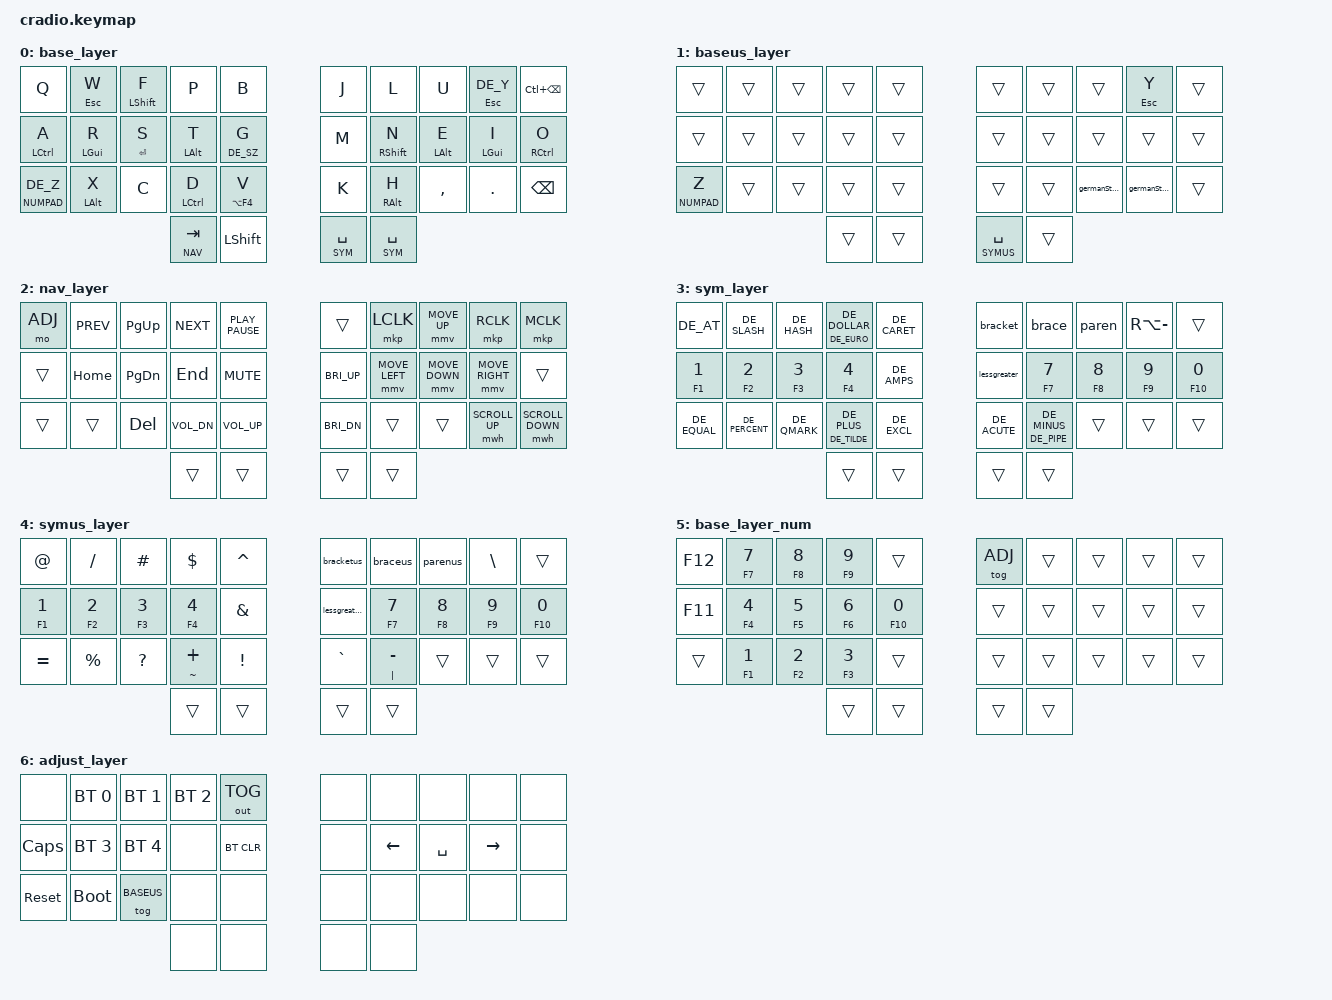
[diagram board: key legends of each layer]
/*
 * Copyright (c) 2020 The ZMK Contributors
 *
 * SPDX-License-Identifier: MIT
 */

#include <behaviors.dtsi>
#include <dt-bindings/zmk/keys.h>
#include <dt-bindings/zmk/bt.h>
#include <dt-bindings/zmk/outputs.h>
#include <dt-bindings/zmk/mouse.h>
#include <dt-bindings/zmk/ext_power.h>
#include "keys_de.h"
#include "../zmk-nodefree-config/helper.h"
#define TAPPING_TIME 25
&mmv {    
        time-to-max-speed-ms = <1000>;
        acceleration-exponent=<1>;
};
&mwh {    
        time-to-max-speed-ms = <1000>;
        acceleration-exponent=<1>;
}; 

#define U_MOUSE_MOVE_MAX 2250       // 600
#define U_MOUSE_SCROLL_MAX 100      // 10

#undef MOVE_UP
#undef MOVE_DOWN
#undef MOVE_LEFT
#undef MOVE_RIGHT
#define MOVE_UP MOVE_VERT(-U_MOUSE_MOVE_MAX)
#define MOVE_DOWN MOVE_VERT(U_MOUSE_MOVE_MAX)
#define MOVE_LEFT MOVE_HOR(-U_MOUSE_MOVE_MAX)
#define MOVE_RIGHT MOVE_HOR(U_MOUSE_MOVE_MAX)

#undef SCROLL_UP
#undef SCROLL_DOWN
#undef SCROLL_LEFT
#undef SCROLL_RIGHT
#define SCROLL_UP SCROLL_VERT(U_MOUSE_SCROLL_MAX)
#define SCROLL_DOWN SCROLL_VERT(-U_MOUSE_SCROLL_MAX)
#define SCROLL_LEFT SCROLL_HOR(-U_MOUSE_SCROLL_MAX)
#define SCROLL_RIGHT SCROLL_HOR(U_MOUSE_SCROLL_MAX)





#define XXX &none
#define ___ &trans

#define BASE 0
#define BASEUS 1
#define NAV 2
#define SYM 3
#define SYMUS 4
#define NUMPAD 5
#define ADJ 6


        /*                KEY POSITIONS
  ╭────────────────────╮ ╭────────────────────╮
  │  0   1   2   3   4 │ │  5   6   7   8   9 │
  │ 10  11  12  13  14 │ │ 15  16  17  18  19 │
  │ 20  21  22  23  24 │ │ 25  26  27  28  29 │
  ╰───────────╮ 30  31 │ │ 32  33 ╭───────────╯
              ╰────────╯ ╰────────╯            */


ZMK_COMBO(pwr,  &kp C_POWER, 0 4, ALL)
ZMK_COMBO(f23,  &kp F23, 10 20, ALL)
ZMK_COMBO(f24,  &kp F24, 19 29, ALL)

ZMK_COMBO(quote,&kp DE_DQT, 8 18, BASE)
ZMK_COMBO(apostroph,  &kp DE_APOS, 0 10, BASE)

ZMK_COMBO(quoteus,&kp DQT, 8 18, BASEUS)
ZMK_COMBO(apostrophus,  &kp APOS, 0 10, BASEUS)

ZMK_COMBO(five,  &kp N5, 3 13, ALL)
ZMK_COMBO(six,  &kp N6, 6 16, ALL)
ZMK_COMBO(ae,  &kp DE_A_UMLAUT, 10 17, BASE)
ZMK_COMBO(ue,  &kp DE_U_UMLAUT, 7 17, BASE)
ZMK_COMBO(oe,  &kp DE_O_UMLAUT, 17 19, BASE)


ZMK_COMBO(up,  &kp UP, 11 12 13, ALL,15)
ZMK_COMBO(down,  &kp DOWN, 11 13, ALL,15)
ZMK_COMBO(right,  &kp RIGHT, 12 13, ALL,15)
ZMK_COMBO(left,  &kp LEFT, 11 12, ALL,15)


ZMK_COMBO(scCombo,  &scModMorph, 12 22, BASE BASEUS)
ZMK_COMBO(ecommaCombo,  &ecomma, 17 27, BASE BASEUS)

//home row mods
ZMK_BEHAVIOR(hm, hold_tap,
    flavor = "tap-preferred";
    tapping-term-ms = <280>;
    quick-tap-ms = <125>;
    global-quick-tap;
    bindings = <&kp>, <&kp>;
)
ZMK_BEHAVIOR(hma, hold_tap,
    flavor = "tap-preferred";
    tapping-term-ms = <280>;
    quick-tap-ms = <125>;
    global-quick-tap;
    bindings = <&kp>, <&amac>;
)
ZMK_BEHAVIOR(hmr, hold_tap,
    flavor = "tap-preferred";
    tapping-term-ms = <280>;
    quick-tap-ms = <125>;
    global-quick-tap;
    bindings = <&kp>, <&rmac>;
)
ZMK_BEHAVIOR(hms, hold_tap,
    flavor = "tap-preferred";
    tapping-term-ms = <280>;
    quick-tap-ms = <125>;
    global-quick-tap;
    bindings = <&kp>, <&smac>;
)
ZMK_BEHAVIOR(hmt, hold_tap,
    flavor = "tap-preferred";
    tapping-term-ms = <280>;
    quick-tap-ms = <125>;
    global-quick-tap;
    bindings = <&kp>, <&tmac>;
)
ZMK_BEHAVIOR(hmn, hold_tap,
    flavor = "tap-preferred";
    tapping-term-ms = <280>;
    quick-tap-ms = <125>;
    global-quick-tap;
    bindings = <&kp>, <&nmac>;
)
ZMK_BEHAVIOR(hme, hold_tap,
    flavor = "tap-preferred";
    tapping-term-ms = <280>;
    quick-tap-ms = <125>;
    global-quick-tap;
    bindings = <&kp>, <&emac>;
)
ZMK_BEHAVIOR(hmi, hold_tap,
    flavor = "tap-preferred";
    tapping-term-ms = <280>;
    quick-tap-ms = <125>;
    global-quick-tap;
    bindings = <&kp>, <&imac>;
)
ZMK_BEHAVIOR(hmo, hold_tap,
    flavor = "tap-preferred";
    tapping-term-ms = <280>;
    quick-tap-ms = <125>;
    global-quick-tap;
    bindings = <&kp>, <&omac>;
)

//macros

    
ZMK_BEHAVIOR(ecomma, macro,
    wait-ms = <0>;
    tap-ms = <0>;
    bindings = <&kp E &kp COMMA>;)
ZMK_BEHAVIOR(sc, macro,
    wait-ms = <0>;
    tap-ms = <0>;
    bindings = <&kp S &kp C>;)
ZMK_BEHAVIOR(capitalSlowC, macro,
    wait-ms = <0>;
    tap-ms = <0>;
    bindings = <&kp LS(S) &kp C >;)

ZMK_BEHAVIOR(bracket, macro,
    wait-ms = <0>;
    tap-ms = <0>;
    bindings = <&kp DE_LEFT_BRACKET &kp DE_RIGHT_BRACKET &kp LEFT >;)
ZMK_BEHAVIOR(brace, macro,
    wait-ms = <0>;
    tap-ms = <0>;
    bindings = <&kp DE_LEFT_BRACE &kp DE_RIGHT_BRACE &kp LEFT >;)
ZMK_BEHAVIOR(paren, macro,
    wait-ms = <0>;
    tap-ms = <0>;
    bindings = <&kp DE_LEFT_PARENTHESIS &kp DE_RIGHT_PARENTHESIS &kp LEFT >;)
ZMK_BEHAVIOR(lessgreater, macro,
    wait-ms = <0>;
    tap-ms = <0>;
    bindings = <&kp DE_LESS_THAN &kp DE_GREATER_THAN &kp LEFT >;)


ZMK_BEHAVIOR(bracketus, macro,
    wait-ms = <0>;
    tap-ms = <0>;
    bindings = <&kp LEFT_BRACKET &kp RIGHT_BRACKET &kp LEFT >;)
ZMK_BEHAVIOR(braceus, macro,
    wait-ms = <0>;
    tap-ms = <0>;
    bindings = <&kp LEFT_BRACE &kp RIGHT_BRACE &kp LEFT >;)
ZMK_BEHAVIOR(parenus, macro,
    wait-ms = <0>;
    tap-ms = <0>;
    bindings = <&kp LEFT_PARENTHESIS &kp RIGHT_PARENTHESIS &kp LEFT >;)
ZMK_BEHAVIOR(lessgreaterus, macro,
    wait-ms = <0>;
    tap-ms = <0>;
    bindings = <&kp LT &kp GT &kp LEFT >;)



 ZMK_BEHAVIOR(amac, macro,
    wait-ms = <0>;
    tap-ms = <30>;
    bindings = <&kp A>;)
     ZMK_BEHAVIOR(rmac, macro,
    wait-ms = <0>;
    tap-ms = <30>;
    bindings = <&kp R>;)
     ZMK_BEHAVIOR(smac, macro,
    wait-ms = <0>;
    tap-ms = <30>;
    bindings = <&kp S>;)
     ZMK_BEHAVIOR(tmac, macro,
    wait-ms = <0>;
    tap-ms = <30>;
    bindings = <&kp T>;)
     ZMK_BEHAVIOR(nmac, macro,
    wait-ms = <0>;
    tap-ms = <30>;
    bindings = <&kp N>;)
     ZMK_BEHAVIOR(emac, macro,
    wait-ms = <0>;
    tap-ms = <30>;
    bindings = <&kp E>;)
     ZMK_BEHAVIOR(imac, macro,
    wait-ms = <0>;
    tap-ms = <30>;
    bindings = <&kp I>;)
     ZMK_BEHAVIOR(omac, macro,
    wait-ms = <0>;
    tap-ms = <30>;
    bindings = <&kp O>;)


//mod morph
ZMK_BEHAVIOR(scModMorph, mod_morph,
    bindings = <&sc>, <&capitalSlowC>;
    mods = <(MOD_LSFT|MOD_RSFT)>;
)

ZMK_BEHAVIOR(germanStyeDot, mod_morph,
    bindings = <&kp DOT>, <&kp COLON>;
    mods = <(MOD_LSFT|MOD_RSFT)>;
)

ZMK_BEHAVIOR(germanStyeComma, mod_morph,
    bindings = <&kp DOT>, <&kp SEMICOLON>;
    mods = <(MOD_LSFT|MOD_RSFT)>;
)

/ {



  keymap {
    compatible = "zmk,keymap";

    base_layer {
      bindings = <
        // ╭─────────────┬─────────────┬─────────────┬─────────────┬─────────────╮   ╭─────────────┬─────────────┬─────────────┬─────────────┬─────────────╮
                 &kp Q      &hm ESC W    &hm LSHIFT F    &kp P         &kp B             &kp J          &kp L        &kp U       &hm ESC DE_Y  &kp LC(BSPC)
        // ├─────────────┼─────────────┼─────────────┼─────────────┼─────────────┤   ├─────────────┼─────────────┼─────────────┼─────────────┼─────────────┤
            &hma LCTRL A     &hmr LGUI R   &hms RET S  &hmt LALT T    &hm DE_SZ G         &kp M       &hmn RSHFT N   &hme LALT E   &hmi LGUI I    &hmo RCTRL O
        // ├─────────────┼─────────────┼─────────────┼─────────────┼─────────────┤   ├─────────────┼─────────────┼─────────────┼─────────────┼─────────────┤
          &lt NUMPAD DE_Z   &hm LALT X      &kp C      &hm LCTRL D   &hm LA(F4) V        &kp K       &hm RALT H    &kp COMMA     &kp DOT       &kp BSPC
        // ╰─────────────┴─────────────┴─────────────┼─────────────┼─────────────┤   ├─────────────┼─────────────┼─────────────┴─────────────┴─────────────╯
                                                       &lt NAV TAB   &kp LSHFT          &lt SYM SPC   &lt SYM SPC
        //                                           ╰─────────────┴─────────────╯   ╰─────────────┴─────────────╯
      >;
    };

    baseus_layer {
      bindings = <
        // ╭─────────────┬─────────────┬─────────────┬─────────────┬─────────────╮   ╭─────────────┬─────────────┬─────────────┬─────────────┬─────────────╮
                 ___           ___           ___           ___           ___               ___           ___           ___       &hm ESC Y         ___
        // ├─────────────┼─────────────┼─────────────┼─────────────┼─────────────┤   ├─────────────┼─────────────┼─────────────┼─────────────┼─────────────┤
                 ___           ___           ___           ___           ___               ___           ___           ___           ___           ___
        // ├─────────────┼─────────────┼─────────────┼─────────────┼─────────────┤   ├─────────────┼─────────────┼─────────────┼─────────────┼─────────────┤
            &lt NUMPAD Z       ___           ___           ___           ___               ___           ___     &germanStyeComma &germanStyeDot   ___
        // ╰─────────────┴─────────────┴─────────────┼─────────────┼─────────────┤   ├─────────────┼─────────────┼─────────────┴─────────────┴─────────────╯
                                                           ___           ___           &lt SYMUS SPC     ___
        //                                           ╰─────────────┴─────────────╯   ╰─────────────┴─────────────╯
      >;
    };
      

    nav_layer {
      bindings = <
        // ╭─────────────┬─────────────┬─────────────┬─────────────┬─────────────╮   ╭─────────────┬─────────────┬─────────────┬─────────────┬─────────────╮
               &mo ADJ      &kp C_PREV     &kp PG_UP      &kp C_NEXT   &kp K_PLAY_PAUSE           ___        &mkp LCLK    &mmv MOVE_UP   &mkp RCLK     &mkp MCLK
        // ├─────────────┼─────────────┼─────────────┼─────────────┼─────────────┤   ├─────────────┼─────────────┼─────────────┼─────────────┼─────────────┤
                 ___        &kp HOME      &kp PG_DN      &kp END      &kp C_MUTE       &kp C_BRI_UP &mmv MOVE_LEFT &mmv MOVE_DOWN &mmv MOVE_RIGHT   ___
        // ├─────────────┼─────────────┼─────────────┼─────────────┼─────────────┤   ├─────────────┼─────────────┼─────────────┼─────────────┼─────────────┤
                 ___           ___         &kp DEL     &kp C_VOL_DN  &kp C_VOL_UP      &kp C_BRI_DN     ___             ___      &mwh SCROLL_UP &mwh SCROLL_DOWN
        // ╰─────────────┴─────────────┴─────────────┼─────────────┼─────────────┤   ├─────────────┼─────────────┼─────────────┴─────────────┴─────────────╯
                                                           ___           ___               ___           ___
        //                                           ╰─────────────┴─────────────╯   ╰─────────────┴─────────────╯
      >;
    };

    sym_layer {
      bindings = <
        // ╭─────────────┬─────────────┬─────────────┬─────────────┬─────────────╮   ╭─────────────┬─────────────┬─────────────┬─────────────┬─────────────╮
            &kp DE_AT   &kp DE_SLASH  &kp DE_HASH &hm DE_EURO DE_DOLLAR &kp DE_CARET     &bracket      &brace         &paren     &kp RA(MINUS)     ___
        // ├─────────────┼─────────────┼─────────────┼─────────────┼─────────────┤   ├─────────────┼─────────────┼─────────────┼─────────────┼─────────────┤
               &hm F1 N1    &hm F2 N2    &hm F3 N3      &hm F4 N4    &kp DE_AMPS       &lessgreater &hm F7 N7     &hm F8 N8    &hm F9 N9     &hm F10 N0
        // ├─────────────┼─────────────┼─────────────┼─────────────┼─────────────┤   ├─────────────┼─────────────┼─────────────┼─────────────┼─────────────┤
             &kp DE_EQUAL  &kp DE_PERCENT &kp DE_QMARK &hm DE_TILDE DE_PLUS  &kp DE_EXCL      &kp DE_ACUTE &hm DE_PIPE DE_MINUS ___           ___           ___
        // ╰─────────────┴─────────────┴─────────────┼─────────────┼─────────────┤   ├─────────────┼─────────────┼─────────────┴─────────────┴─────────────╯
                                                           ___           ___               ___          ___
        //                                           ╰─────────────┴─────────────╯   ╰─────────────┴─────────────╯
      >;
    };

      symus_layer {
      bindings = <
        // ╭─────────────┬─────────────┬─────────────┬─────────────┬─────────────╮   ╭─────────────┬─────────────┬─────────────┬─────────────┬─────────────╮
               &kp AT       &kp SLASH     &kp HASH     &kp DOLLAR     &kp CARET         &bracketus    &braceus     &parenus     &kp BACKSLASH     ___
        // ├─────────────┼─────────────┼─────────────┼─────────────┼─────────────┤   ├─────────────┼─────────────┼─────────────┼─────────────┼─────────────┤
               &hm F1 N1    &hm F2 N2    &hm F3 N3      &hm F4 N4    &kp AMPS        &lessgreaterus &hm F7 N7     &hm F8 N8    &hm F9 N9     &hm F10 N0
        // ├─────────────┼─────────────┼─────────────┼─────────────┼─────────────┤   ├─────────────┼─────────────┼─────────────┼─────────────┼─────────────┤
             &kp EQUAL     &kp PERCENT    &kp QMARK     &hm TILDE PLUS      &kp EXCL           &kp GRAVE  &hm PIPE MINUS     ___           ___           ___
        // ╰─────────────┴─────────────┴─────────────┼─────────────┼─────────────┤   ├─────────────┼─────────────┼─────────────┴─────────────┴─────────────╯
                                                           ___           ___               ___          ___
        //                                           ╰─────────────┴─────────────╯   ╰─────────────┴─────────────╯
      >;
    };

    base_layer_num {
      bindings = <
        // ╭─────────────┬─────────────┬─────────────┬─────────────┬─────────────╮   ╭─────────────┬─────────────┬─────────────┬─────────────┬─────────────╮
               &kp F12      &hm F7 N7     &hm F8 N8    &hm F9 N9         ___               &tog ADJ           ___           ___           ___           ___
        // ├─────────────┼─────────────┼─────────────┼─────────────┼─────────────┤   ├─────────────┼─────────────┼─────────────┼─────────────┼─────────────┤
               &kp F11      &hm F4 N4     &hm F5 N5    &hm F6 N6     &hm F10 N0            ___           ___           ___           ___           ___
        // ├─────────────┼─────────────┼─────────────┼─────────────┼─────────────┤   ├─────────────┼─────────────┼─────────────┼─────────────┼─────────────┤
                 ___        &hm F1 N1     &hm F2 N2    &hm F3 N3         ___               ___           ___           ___           ___           ___
        // ╰─────────────┴─────────────┴─────────────┼─────────────┼─────────────┤   ├─────────────┼─────────────┼─────────────┴─────────────┴─────────────╯
                                                           ___           ___               ___           ___
        //                                           ╰─────────────┴─────────────╯   ╰─────────────┴─────────────╯
      >;
    };

    adjust_layer {
      bindings = <
        // ╭─────────────┬─────────────┬─────────────┬─────────────┬─────────────╮   ╭─────────────┬─────────────┬─────────────┬─────────────┬─────────────╮
             XXX           &bt BT_SEL 0 &bt BT_SEL 1 &bt BT_SEL 2   &out OUT_TOG           XXX           XXX           XXX           XXX           XXX
        // ├─────────────┼─────────────┼─────────────┼─────────────┼─────────────┤   ├─────────────┼─────────────┼─────────────┼─────────────┼─────────────┤
                &kp CAPS  &bt BT_SEL 3   &bt BT_SEL 4     XXX        &bt BT_CLR           XXX           &kp LEFT    &kp SPC           &kp RIGHT           XXX
        // ├─────────────┼─────────────┼─────────────┼─────────────┼─────────────┤   ├─────────────┼─────────────┼─────────────┼─────────────┼─────────────┤
            &sys_reset     &bootloader   &tog BASEUS       XXX           XXX               XXX           XXX           XXX       XXX    XXX
        // ╰─────────────┴─────────────┴─────────────┼─────────────┼─────────────┤   ├─────────────┼─────────────┼─────────────┴─────────────┴─────────────╯
                                                           XXX           XXX               XXX           XXX
        //                                           ╰─────────────┴─────────────╯   ╰─────────────┴─────────────╯
      >;
    };
  };
};
